# ATmega128A register map
Vendor: Atmel; File version: 1.0
CPU: other r0p0, little endian, no MPU, no FPU, 4 interrupt priority bits
Registers are 8-bit, read-write, reset 0x0 unless marked. A register's access mark holds for its fields unless they carry their own. Offsets are from the block's base; [hi:lo] are bit positions.

## TWI — Two Wire Serial Interface
Base 0x00800070
0x00 TWBR — TWI Bit Rate register
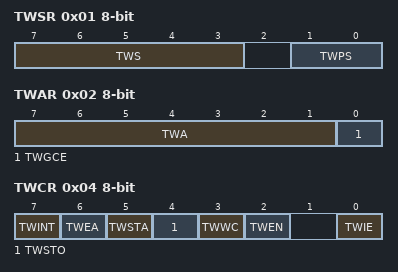
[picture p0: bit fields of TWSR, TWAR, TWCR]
0x01 TWSR — TWI Status Register
  [7:3] TWS — TWI Status
  [1:0] TWPS — TWI Prescaler
    0=1; 1=4; 2=16; 3=64
0x02 TWAR — TWI (Slave) Address register
  [7:1] TWA — TWI (Slave) Address register Bits
  [0] TWGCE — TWI General Call Recognition Enable Bit
0x03 TWDR — TWI Data register
0x04 TWCR — TWI Control Register (read-only for debugger)
  [7] TWINT — TWI Interrupt Flag
  [6] TWEA — TWI Enable Acknowledge Bit
  [5] TWSTA — TWI Start Condition Bit
  [4] TWSTO — TWI Stop Condition Bit
  [3] TWWC — TWI Write Collision Flag
  [2] TWEN — TWI Enable Bit
  [0] TWIE — TWI Interrupt Enable

## USART0 — USART
Base 0x00800029
0x00 UBRR0L — USART Baud Rate Register Low Byte
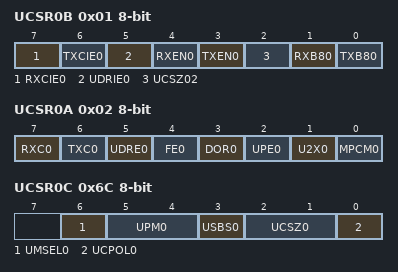
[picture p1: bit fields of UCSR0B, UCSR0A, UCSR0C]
0x01 UCSR0B — USART Control and Status Register B
  [7] RXCIE0 — RX Complete Interrupt Enable
  [6] TXCIE0 — TX Complete Interrupt Enable
  [5] UDRIE0 — USART Data register Empty Interrupt Enable
  [4] RXEN0 — Receiver Enable
  [3] TXEN0 — Transmitter Enable
  [2] UCSZ02 — Character Size
  [1] RXB80 — Receive Data Bit 8
  [0] TXB80 — Transmit Data Bit 8
0x02 UCSR0A — USART Control and Status Register A (read-only for debugger)
  [7] RXC0 ro — USART Receive Complete
  [6] TXC0 — USART Transmit Complete
  [5] UDRE0 ro — USART Data Register Empty
  [4] FE0 ro — Framing Error
  [3] DOR0 ro — Data overRun
  [2] UPE0 ro — Parity Error
  [1] U2X0 — Double the USART transmission speed
  [0] MPCM0 — Multi-processor Communication Mode
0x03 UDR0 — USART I/O Data Register (write-only for debugger)
0x67 UBRR0H — USART Baud Rate Register High Byte
0x6C UCSR0C — USART Control and Status Register C
  [6] UMSEL0 — USART Mode Select
    0=ASYNCHRONOUS_OPERATION; 1=SYNCHRONOUS_OPERATION
  [5:4] UPM0 — Parity Mode Bits
    0=DISABLED; 2=ENABLED_EVEN_PARITY; 3=ENABLED_ODD_PARITY
  [3] USBS0 — Stop Bit Select
    0=1_BIT; 1=2_BIT
  [2:1] UCSZ0 — Character Size
  [0] UCPOL0 — Clock Polarity

## USART1 — USART
Base 0x00800098
0x00 UBRR1H — USART Baud Rate Register High Byte
0x01 UBRR1L — USART Baud Rate Register Low Byte
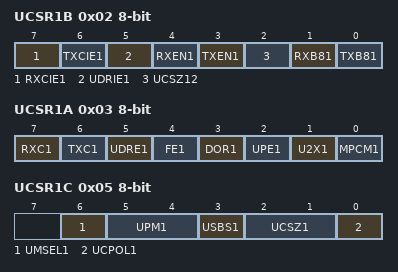
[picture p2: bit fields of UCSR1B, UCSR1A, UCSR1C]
0x02 UCSR1B — USART Control and Status Register B
  [7] RXCIE1 — RX Complete Interrupt Enable
  [6] TXCIE1 — TX Complete Interrupt Enable
  [5] UDRIE1 — USART Data register Empty Interrupt Enable
  [4] RXEN1 — Receiver Enable
  [3] TXEN1 — Transmitter Enable
  [2] UCSZ12 — Character Size
  [1] RXB81 — Receive Data Bit 8
  [0] TXB81 — Transmit Data Bit 8
0x03 UCSR1A — USART Control and Status Register A (read-only for debugger)
  [7] RXC1 — USART Receive Complete
  [6] TXC1 — USART Transmit Complete
  [5] UDRE1 — USART Data Register Empty
  [4] FE1 — Framing Error
  [3] DOR1 — Data overRun
  [2] UPE1 — Parity Error
  [1] U2X1 — Double the USART transmission speed
  [0] MPCM1 — Multi-processor Communication Mode
0x04 UDR1 — USART I/O Data Register (write-only for debugger)
0x05 UCSR1C — USART Control and Status Register C
  [6] UMSEL1 — USART Mode Select
    0=ASYNCHRONOUS_OPERATION; 1=SYNCHRONOUS_OPERATION
  [5:4] UPM1 — Parity Mode Bits
    0=DISABLED; 2=ENABLED_EVEN_PARITY; 3=ENABLED_ODD_PARITY
  [3] USBS1 — Stop Bit Select
    0=1_BIT; 1=2_BIT
  [2:1] UCSZ1 — Character Size
  [0] UCPOL1 — Clock Polarity

## WDT — Watchdog Timer
Base 0x00800041
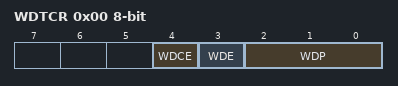
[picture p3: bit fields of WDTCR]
0x00 WDTCR — Watchdog Timer Control Register
  [4] WDCE — Watchdog Change Enable
  [3] WDE — Watch Dog Enable
  [2:0] WDP — Watch Dog Timer Prescaler bits
    0=OSCILLATOR_CYCLES_16K; 1=OSCILLATOR_CYCLES_32K; 2=OSCILLATOR_CYCLES_64K; 3=OSCILLATOR_CYCLES_128K; 4=OSCILLATOR_CYCLES_256K; 5=OSCILLATOR_CYCLES_512K; 6=OSCILLATOR_CYCLES_1024K; 7=OSCILLATOR_CYCLES_2048K
